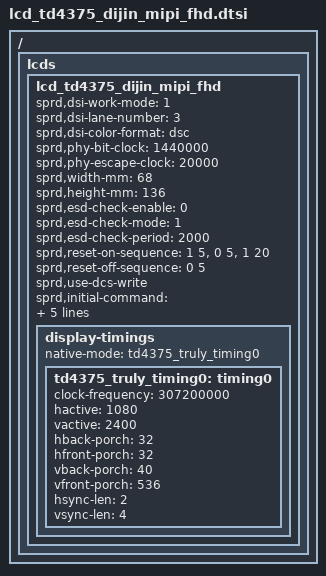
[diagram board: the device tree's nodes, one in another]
/ {
	fragment {
		target-path = "/";
		__overlay__ {
			lcds {
				lcd_td4375_dijin_mipi_fhd: lcd_td4375_dijin_mipi_fhd {

					sprd,dsi-work-mode = <1>; /* video burst mode*/
					sprd,dsi-lane-number = <3>;
					sprd,dsi-color-format = "dsc";

					sprd,phy-bit-clock = <1440000>;
					sprd,phy-escape-clock = <20000>;/* kHz */

					sprd,width-mm = <68>;
					sprd,height-mm = <136>;

					sprd,esd-check-enable = <0>;
					sprd,esd-check-mode = <1>;
					sprd,esd-check-period = <2000>;

					sprd,reset-on-sequence = <1 5>, <0 5>, <1 20>;
					sprd,reset-off-sequence = <0 5>;

					sprd,use-dcs-write;

					sprd,initial-command = [
						39 00 00 02 B0 00
						39 00 00 0B B6 20 6b 00 86 03 0a 13 1a 00 00
						39 00 00 05 B7 51 00 00 00
						39 00 00 08 B8 57 3d 19 be 1e 0a 0a
						39 00 00 08 B9 6f 3d 28 be 3c 14 0a
						39 00 00 08 BA b5 33 41 be 64 23 0a
						39 00 00 0C BB 44 26 c3 1f 19 06 03 c0 00 00 10
						39 00 00 0C BC 32 4c c3 52 32 1f 03 f2 00 00 13
						39 00 00 0C BD 24 68 c3 aa 3f 32 03 ff 00 00 25
						39 00 00 0D BE 00 00 00 00 00 00 00 00 00 00 00 00
						39 00 00 18 C0 00 68 01 2c 08 09 60 02 6c 22 00 08 00 70 00 00 00 00 00 00 00 00 02
						39 00 00 35 C1 30 00 00 11 00 00 00 00 22 00 05 20 00 80 fa 40 00 84 0f 00 00 00 00 00 00 00 00 00 00 00 00 00 00 00 00 00 00 00 00 00 00 01 2c 08 08 00 0a 28 0f 3c 14 50
						39 00 00 8E C2 03 40 34 01 03 10 02 00 00 00 00 00 00 00 00 00 00 00 00 00 00 00 00 00 00 00 00 00 00 00 00 00 00 00 00 00 00 00 00 00 02 00 00 00 00 00 11 00 00 00 00 00 00 01 f0 56 00 00 00 00 c0 00 00 00 00 00 01 00 00 00 00 00 11 00 00 00 00 00 00 00 00 00 00 00 00 00 00 00 00 00 00 00 00 00 00 00 11 00 00 00 00 00 00 00 00 68 00 00 00 04 c0 00 00 04 00 00 00 00 00 00 11 00 00 04 00 00 00 00 00 00 00 00 00 00 00 00 00 00 00 00 00
						39 00 00 6D C3 00 00 00 00 00 00 00 00 00 00 00 00 00 00 00 00 00 00 00 00 00 00 00 00 00 00 00 00 00 00 00 00 00 00 00 00 00 00 00 00 00 00 00 00 00 00 00 00 00 00 00 00 00 00 00 00 00 00 00 00 00 00 aa aa aa 00 00 00 00 00 00 00 00 00 00 00 00 00 00 00 00 00 00 00 00 00 00 00 00 00 00 00 00 00 00 00 00 00 00 00 00 00 00 00 00 00 00 00
						39 00 00 6E C4 00 4c 00 3f 00 83 00 00 87 86 85 84 00 00 00 00 00 5d 61 5f 00 62 60 5e 00 00 00 02 00 83 00 00 87 86 85 84 00 00 00 00 00 5d 61 5f 00 62 60 5e ff ff ff ff ff ff 00 0f 0e 00 0f 0e 00 00 00 00 00 00 00 0f 00 00 0f 00 00 00 00 00 00 00 03 03 00 00 03 03 00 00 00 00 ff 07 55 00 00 00 00 00 00 00 00 00 00 00 00 00 00 00 00 00 00
						39 00 00 06 C5 08 00 00 00 00
						39 00 00 3F C6 03 0a 0e 10 ff ff ff 00 00 13 01 af 00 01 00 1e 1f 1f 00 00 00 01 05 09 28 28 03 00 20 1c 1a 01 0b 00 00 00 1e 01 00 00 00 00 00 00 20 20 00 00 00 00 00 00 00 00 22 22 00 00 00 00 10 00
						39 00 00 0F CB 20 80 70 00 20 00 00 2d 41 00 00 00 00 ff
						39 00 00 02 CD 00
						39 00 00 24 CE 5d 40 49 53 59 5e 63 68 6e 74 7e 8a 98 a8 bb d0 e7 ff 04 00 04 04 42 40 69 5a 40 11 f4 00 00 04 fa 00 00
						39 00 00 07 CF 89 00 80 46 61 00
						39 00 00 13 D0 cc 14 d5 66 09 b0 00 cf cf e5 d4 0a 52 fe 09 09 cf 00
						39 00 00 2C D1 d3 d3 1b b0 07 07 3b 33 33 33 33 05 33 7b 07 33 3b 78 d2 d2 06 96 13 93 22 22 22 b3 bb 00 00 bb bb 11 08 08 84 00 09 77 ff 11 44
						39 00 00 03 D2 00 00
						39 00 00 18 D4 00 00 00 00 00 00 00 00 00 00 00 00 00 00 00 00 00 00 00 00 00 00 00
						39 00 00 4B D7 21 10 52 52 00 68 00 06 10 68 04 fd 01 00 03 03 05 05 00 03 04 05 00 04 03 08 02 08 06 03 08 04 08 10 0c 0b 0a 0a 0a 07 08 0a 06 00 08 00 04 05 09 00 04 04 04 04 04 04 04 02 04 04 04 04 04 04 04 04 04 04 06 06 05 05 05 00
						39 00 00 3F D8 00 12 00 00 00 00 00 00 00 00 00 00 00 00 00 00 00 00 00 00 00 00 00 00 00 00 00 00 00 00 00 00 00 00 00 00 00 00 00 00 00 00 00 00 00 00 00 00 00 00 00 00 00 00 00 00 00 00 00 00 00 00
						39 00 00 17 D9 42 97 26 ed 0e ba 16 6c 16 6c 00 30 00 14 00 14 00 0c 00 00 01 00
						39 00 00 05 DD 30 06 23 65
						39 00 00 0B DE 00 00 00 0f ff 00 00 00 00 10
						39 00 00 0B E6 00 00 00 00 00 00 00 00 00 00
						39 00 00 7E E7 11 00 89 30 80 09 60 04 38 09 60 02 1c 02 1c 02 00 02 0e 20 e1 3f 00 07 0c 00 0b 00 0b 18 00 10 f0 03 0c 20 00 06 0b 0b 33 0e 1c 2a 38 46 54 62 69 70 77 79 7b 7d 7e 01 02 01 00 09 40 09 be 19 fc 19 fa 19 f8 1a 38 1a 78 1a b6 2a f6 2b 34 2b 74 3b 74 6b f4 00 00 00 00 00 00 00 00 00 00 00 00 00 00 00 00 00 00 00 00 00 00 00 00 00 00 00 00 00 00 00 00 00 00 00 00 00 00 00 00
						39 00 00 05 E8 00 31 33 00
						39 00 00 1F EA 01 0a 0a 00 12 c0 00 00 19 08 01 ff 00 00 00 00 00 00 00 00 04 c2 00 12 00 68 06 80 86 00
						39 00 00 08 EB 00 00 00 00 01 00 11
						39 00 00 0B EC 05 f0 00 10 b9 12 c0 00 02 3a
						39 00 00 21 ED 01 01 02 02 08 08 09 09 00 00 00 00 02 00 00 00 00 0e 01 f2 00 00 00 50 00 01 f2 00 00 a0 10 00
						39 00 00 61 EE 01 0f 00 00 00 00 40 1f 00 00 0f 02 3f 00 00 00 00 00 00 00 00 00 00 00 00 00 00 00 10 01 00 09 01 00 00 00 00 00 00 00 00 00 00 00 00 00 00 00 00 00 00 00 00 00 50 1f 00 00 00 00 00 00 00 00 00 00 00 00 00 00 00 00 00 00 00 00 00 00 00 00 00 00 00 00 00 00 00 00 00 00 00 00 00 00 00 00
						39 00 00 54 EF 00 40 1f 03 d0 00 00 00 00 15 18 18 00 00 00 00 00 00 00 00 00 00 a0 23 03 c0 15 18 18 00 00 00 00 00 00 10 01 10 01 00 10 00 10 00 0a 06 00 00 00 00 00 43 00 03 51 00 00 05 00 00 00 00 00 00 00 00 00 00 00 00 00 00 00 00 00 00 00 00 00 00 01 00 01
						39 00 00 09 F9 44 3f 00 8d bf 00 09 1d
						39 00 00 02 B0 03
						39 00 00 02 B0 04
						39 00 00 05 E5 03 00 00 00
						39 00 00 05 D5 00 21 00 21
						39 00 00 02 D6 00
						39 00 00 4D C7 00 00 00 E5 01 63 01 8C 01 A2 01 A8 01 AF 01 A7 01 BE 01 8B 01 DA 01 93 01 D0 01 82 01 E3 01 CE 02 49 02 A5 02 AF 00 00 00 E5 01 63 01 8C 01 A2 01 A8 01 AF 01 A7 01 BE 01 8B 01 DA 01 93 01 D0 01 82 01 E3 01 CE 02 49 02 A5 02 AF
						39 00 00 02 51 FF
						39 00 00 02 53 0C
						39 00 00 02 55 00
						39 00 00 02 B0 03
						05 78 00 01 11
						05 0a 00 01 29
						];

					sprd,sleep-in-command = [
						05 0A 00 01 28
						05 78 00 01 10
						];
					sprd,sleep-out-command = [
						05 78 00 01 11
						05 64 00 01 29
						];

					display-timings {
						native-mode = <&td4375_truly_timing0>;

						td4375_truly_timing0: timing0 {
							clock-frequency = <307200000>;
							hactive = <1080>;
							vactive = <2400>;
							hback-porch = <32>;
							hfront-porch = <32>;
							vback-porch = <40>;
							vfront-porch = <536>;
							hsync-len = <2>;
							vsync-len = <4>;
						};
					};
				};
			};
		};
	};
};
